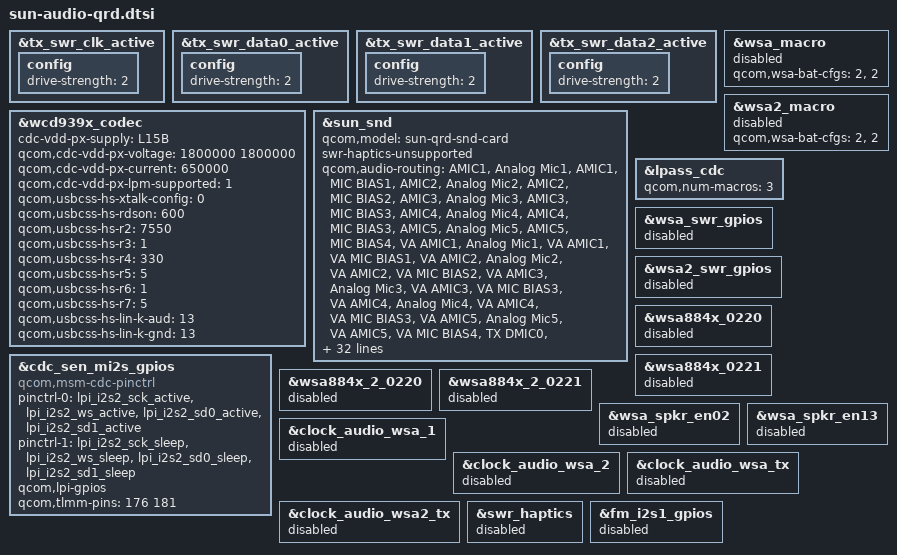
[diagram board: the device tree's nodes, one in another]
// SPDX-License-Identifier: BSD-3-Clause
/*
 * Copyright (c) 2023 Qualcomm Innovation Center, Inc. All rights reserved.
 */

#include "sun-audio-overlay.dtsi"
&tx_swr_clk_active {
	config {
		drive-strength = <2>;
	};
};

&tx_swr_data0_active {
	config {
		drive-strength = <2>;
	};
};

&tx_swr_data1_active {
	config {
		drive-strength = <2>;
	};
};

&tx_swr_data2_active {
	config {
		drive-strength = <2>;
	};
};

&wsa_macro {
	status = "disabled";
	qcom,wsa-bat-cfgs = <2>, <2>;
};

&wsa2_macro {
        status = "disabled";
	qcom,wsa-bat-cfgs = <2>, <2>;
};

&wcd939x_codec {
	cdc-vdd-px-supply = <&L15B>;
	qcom,cdc-vdd-px-voltage = <1800000 1800000>;
	qcom,cdc-vdd-px-current = <650000>;
	qcom,cdc-vdd-px-lpm-supported = <1>;
	/* 0 for digital crosstalk disabled,
	 * 1 for digital crosstalk with local sensed a-xtalk enabled, and
	 * 2 for digital crosstalk with remote sensed a-xtalk enabled.
	 */
	qcom,usbcss-hs-xtalk-config = <0>;
	qcom,usbcss-hs-rdson = <600>;
	qcom,usbcss-hs-r2 = <7550>;
	qcom,usbcss-hs-r3 = <1>;
	qcom,usbcss-hs-r4 = <330>;
	qcom,usbcss-hs-r5 = <5>;
	qcom,usbcss-hs-r6 = <1>;
	qcom,usbcss-hs-r7 = <5>;
	qcom,usbcss-hs-lin-k-aud = <13>;
	qcom,usbcss-hs-lin-k-gnd = <13>;
};
&sun_snd {
	qcom,model = "sun-qrd-snd-card";
        swr-haptics-unsupported;
	qcom,audio-routing =
		"AMIC1", "Analog Mic1",
		"AMIC1", "MIC BIAS1",
		"AMIC2", "Analog Mic2",
		"AMIC2", "MIC BIAS2",
		"AMIC3", "Analog Mic3",
		"AMIC3", "MIC BIAS3",
		"AMIC4", "Analog Mic4",
		"AMIC4", "MIC BIAS3",
		"AMIC5", "Analog Mic5",
		"AMIC5", "MIC BIAS4",
		"VA AMIC1", "Analog Mic1",
		"VA AMIC1", "VA MIC BIAS1",
		"VA AMIC2", "Analog Mic2",
		"VA AMIC2", "VA MIC BIAS2",
		"VA AMIC3", "Analog Mic3",
		"VA AMIC3", "VA MIC BIAS3",
		"VA AMIC4", "Analog Mic4",
		"VA AMIC4", "VA MIC BIAS3",
		"VA AMIC5", "Analog Mic5",
		"VA AMIC5", "VA MIC BIAS4",
		"TX DMIC0", "Digital Mic0",
		"TX DMIC0", "MIC BIAS1",
		"TX DMIC1", "Digital Mic1",
		"TX DMIC1", "MIC BIAS1",
		"TX DMIC2", "Digital Mic2",
		"TX DMIC2", "MIC BIAS3",
		"TX DMIC3", "Digital Mic3",
		"TX DMIC3", "MIC BIAS3",
		"TX DMIC4", "Digital Mic4",
		"TX DMIC4", "MIC BIAS4",
		"TX DMIC5", "Digital Mic5",
		"TX DMIC5", "MIC BIAS4",
		"IN1_HPHL", "HPHL_OUT",
		"IN2_HPHR", "HPHR_OUT",
		"IN3_EAR", "AUX_OUT",
		"RX_TX DEC0_INP", "TX DEC0 MUX",
		"RX_TX DEC1_INP", "TX DEC1 MUX",
		"RX_TX DEC2_INP", "TX DEC2 MUX",
		"RX_TX DEC3_INP", "TX DEC3 MUX",
		"TX SWR_INPUT", "WCD_TX_OUTPUT",
		"VA SWR_INPUT", "VA_SWR_CLK",
		"VA SWR_INPUT", "WCD_TX_OUTPUT",
		"VA_AIF1 CAP", "VA_SWR_CLK",
		"VA_AIF2 CAP", "VA_SWR_CLK",
		"VA_AIF3 CAP", "VA_SWR_CLK",		
		"VA DMIC0", "Digital Mic0",
		"VA DMIC1", "Digital Mic1",
		"VA DMIC2", "Digital Mic2",
		"VA DMIC3", "Digital Mic3",
		"VA DMIC4", "Digital Mic4",
		"VA DMIC5", "Digital Mic5",
		"VA DMIC0", "VA MIC BIAS1",
		"VA DMIC1", "VA MIC BIAS1",
		"VA DMIC2", "VA MIC BIAS3",
		"VA DMIC3", "VA MIC BIAS3",
		"VA DMIC4", "VA MIC BIAS4",
		"VA DMIC5", "VA MIC BIAS4";
        qcom,wcn-bt = <1>;
	asoc-codec  = <&stub_codec>, <&lpass_cdc>,
			<&cs35l45_l>, <&cs35l45_r>,
			<&wcd939x_codec>;
	asoc-codec-names = "msm-stub-codec.1", "lpass-cdc",
			"cs35l45_l", "cs35l45_r",
			"wcd939x_codec";
	qcom,wsa-max-devs = <0>;
	qcom,sen-mi2s-gpios = <&cdc_sen_mi2s_gpios>;
	qcom,msm-mbhc-hs-mic-max-threshold-mv = <1670>;
	qcom,wcd-disable-legacy-surge;
	wcd939x-i2c-handle = <&wcd_usbss>;
};
&cdc_sen_mi2s_gpios {
		status = "ok";
		compatible = "qcom,msm-cdc-pinctrl";
		pinctrl-names = "aud_active", "aud_sleep";
		pinctrl-0 = <&lpi_i2s2_sck_active &lpi_i2s2_ws_active
			     &lpi_i2s2_sd0_active &lpi_i2s2_sd1_active>;
		pinctrl-1 = <&lpi_i2s2_sck_sleep &lpi_i2s2_ws_sleep
			     &lpi_i2s2_sd0_sleep &lpi_i2s2_sd1_sleep>;
		qcom,lpi-gpios;
		qcom,tlmm-pins = <176 181>;
};
&lpass_cdc {
	qcom,num-macros = <3>;
};
&wsa_swr_gpios {
	status = "disabled";
};
&wsa2_swr_gpios {
	status = "disabled";
};
&wsa884x_0220 {
	status = "disabled";
};
&wsa884x_0221 {
	status = "disabled";
};
&wsa884x_2_0220 {
	status = "disabled";
};
&wsa884x_2_0221 {
	status = "disabled";
};
&wsa_spkr_en02 {
	status = "disabled";
};
&wsa_spkr_en13 {
	status = "disabled";
};

&clock_audio_wsa_1 {
	status = "disabled";
};

&clock_audio_wsa_2 {
	status = "disabled";
};

&clock_audio_wsa_tx {
	status = "disabled";
};

&clock_audio_wsa2_tx {
	status = "disabled";
};
&swr_haptics {
	status = "disabled";
};

&fm_i2s1_gpios {
	status = "disabled";
};

